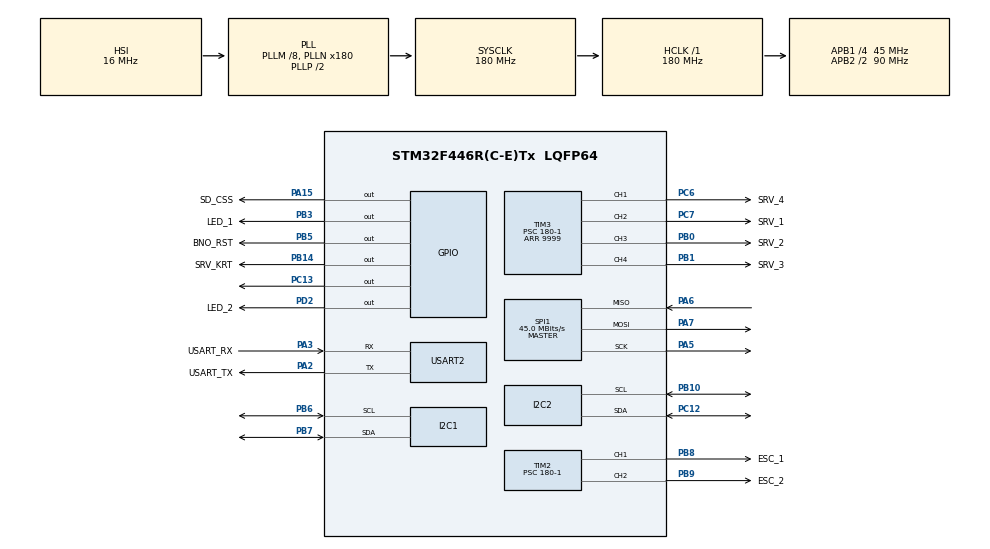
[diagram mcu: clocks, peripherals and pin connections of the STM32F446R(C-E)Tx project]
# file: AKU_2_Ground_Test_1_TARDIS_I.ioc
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FATFS._MAX_SS=4096
FREERTOS.Tasks01=Read_SensorData,3,512,Read_Sensor_Data_Task,Default,NULL,Dynamic,NULL,NULL;Flight_States,2,512,Flight_States_Task,Default,NULL,Dynamic,NULL,NULL;Servo_Control,2,512,Servo_Control_Task,Default,NULL,Dynamic,NULL,NULL;DC_Motor_Contro,2,512,DC_Motor_Control_Task,Default,NULL,Dynamic,NULL,NULL;Uart_to_LTC,0,2048,Uart_to_LTC_Task,Default,NULL,Dynamic,NULL,NULL;Write_to_SD,0,1024,Write_to_SD_Start,Default,NULL,Dynamic,NULL,NULL;System_Check,2,512,System_Check_Start,Default,NULL,Dynamic,NULL,NULL
FREERTOS.configCHECK_FOR_STACK_OVERFLOW=1
FREERTOS.configTOTAL_HEAP_SIZE=45360
FREERTOS.configUSE_NEWLIB_REENTRANT=1
Mcu.Family=STM32F4
Mcu.Name=STM32F446R(C-E)Tx
Mcu.Package=LQFP64
NVIC.PriorityGroup=NVIC_PRIORITYGROUP_4
NVIC.TIM1_UP_TIM10_IRQn=true\:15\:0\:false\:false\:true\:false\:false\:true\:true
NVIC.TimeBase=TIM1_UP_TIM10_IRQn
NVIC.TimeBaseIP=TIM1
NVIC.USART2_IRQn=true\:5\:0\:false\:false\:true\:true\:true\:true\:true
PA13.GPIO_Label=TMS
PA13.Mode=Serial_Wire
PA13.Signal=SYS_JTMS-SWDIO
PA14.GPIO_Label=TCK
PA14.Mode=Serial_Wire
PA14.Signal=SYS_JTCK-SWCLK
PA15.GPIO_Label=SD_CSS
PA15.Signal=GPIO_Output
PA2.GPIO_Label=USART_TX
PA2.Mode=Asynchronous
PA2.Signal=USART2_TX
PA3.GPIO_Label=USART_RX
PA3.Mode=Asynchronous
PA3.Signal=USART2_RX
PA5.Mode=Full_Duplex_Master
PA5.Signal=SPI1_SCK
PA6.Mode=Full_Duplex_Master
PA6.Signal=SPI1_MISO
PA7.Mode=Full_Duplex_Master
PA7.Signal=SPI1_MOSI
PB0.GPIO_Label=SRV_2
PB0.Signal=S_TIM3_CH3
PB1.GPIO_Label=SRV_3
PB1.Signal=S_TIM3_CH4
PB10.Mode=I2C
PB10.Signal=I2C2_SCL
PB14.GPIO_Label=SRV_KRT
PB14.Signal=GPIO_Output
PB3.GPIO_Label=LED_1
PB3.Signal=GPIO_Output
PB5.GPIO_Label=BNO_RST
PB5.Signal=GPIO_Output
PB6.Mode=I2C
PB6.Signal=I2C1_SCL
PB7.Mode=I2C
PB7.Signal=I2C1_SDA
PB8.GPIO_Label=ESC_1
PB8.Signal=S_TIM2_CH1_ETR
PB9.GPIO_Label=ESC_2
PB9.Signal=S_TIM2_CH2
PC12.Mode=I2C
PC12.Signal=I2C2_SDA
PC13.Signal=GPIO_Output
PC14-OSC32_IN.GPIO_Label=LED_3
PC14-OSC32_IN.Mode=LSE-External-Oscillator
PC14-OSC32_IN.Signal=RCC_OSC32_IN
PC15-OSC32_OUT.Mode=LSE-External-Oscillator
PC15-OSC32_OUT.Signal=RCC_OSC32_OUT
PC6.GPIO_Label=SRV_4
PC6.Signal=S_TIM3_CH1
PC7.GPIO_Label=SRV_1
PC7.Signal=S_TIM3_CH2
PD2.GPIO_Label=LED_2
PD2.Signal=GPIO_Output
PH0-OSC_IN.Mode=HSE-External-Oscillator
PH0-OSC_IN.Signal=RCC_OSC_IN
PH1-OSC_OUT.Mode=HSE-External-Oscillator
PH1-OSC_OUT.Signal=RCC_OSC_OUT
ProjectManager.HeapSize=0x200
ProjectManager.StackSize=0x400
ProjectManager.TargetToolchain=STM32CubeIDE
RCC.48MHZClocksFreq_Value=84000000
RCC.AHBFreq_Value=180000000
RCC.APB1CLKDivider=RCC_HCLK_DIV4
RCC.APB1Freq_Value=45000000
RCC.APB1TimFreq_Value=90000000
RCC.APB2CLKDivider=RCC_HCLK_DIV2
RCC.APB2Freq_Value=90000000
RCC.APB2TimFreq_Value=180000000
RCC.CortexFreq_Value=180000000
RCC.FLatency-AdvancedSettings=FLASH_LATENCY_5
RCC.HCLKFreq_Value=180000000
RCC.HSE_VALUE=8000000
RCC.HSI_VALUE=16000000
RCC.PLLM=8
RCC.PLLN=180
RCC.SYSCLKFreq_VALUE=180000000
RCC.SYSCLKSource=RCC_SYSCLKSOURCE_PLLCLK
RCC.USBFreq_Value=180000000
RCC.VCOOutputFreq_Value=360000000
SH.S_TIM2_CH1_ETR.0=TIM2_CH1,PWM Generation1 CH1
SH.S_TIM2_CH2.0=TIM2_CH2,PWM Generation2 CH2
SH.S_TIM3_CH1.0=TIM3_CH1,PWM Generation1 CH1
SH.S_TIM3_CH2.0=TIM3_CH2,PWM Generation2 CH2
SH.S_TIM3_CH3.0=TIM3_CH3,PWM Generation3 CH3
SH.S_TIM3_CH4.0=TIM3_CH4,PWM Generation4 CH4
SPI1.CalculateBaudRate=45.0 MBits/s
SPI1.Direction=SPI_DIRECTION_2LINES
SPI1.Mode=SPI_MODE_MASTER
SPI1.VirtualType=VM_MASTER
TIM2.Channel-PWM\ Generation1\ CH1=TIM_CHANNEL_1
TIM2.Channel-PWM\ Generation2\ CH2=TIM_CHANNEL_2
TIM2.Period=9999
TIM2.Prescaler=180-1
TIM3.Channel-PWM\ Generation1\ CH1=TIM_CHANNEL_1
TIM3.Channel-PWM\ Generation2\ CH2=TIM_CHANNEL_2
TIM3.Channel-PWM\ Generation3\ CH3=TIM_CHANNEL_3
TIM3.Channel-PWM\ Generation4\ CH4=TIM_CHANNEL_4
TIM3.Period=9999
TIM3.Prescaler=180-1
USART2.VirtualMode=VM_ASYNC
VP_FATFS_VS_Generic.Mode=User_defined
VP_FREERTOS_VS_CMSIS_V1.Mode=CMSIS_V1
VP_SYS_VS_tim1.Mode=TIM1
VP_TIM2_VS_ClockSourceINT.Mode=Internal
VP_TIM3_VS_ClockSourceINT.Mode=Internal
board=NUCLEO-F446RE

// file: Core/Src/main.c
/* USER CODE BEGIN Header */
/**
  ******************************************************************************
  * @file           : main.c
  * @brief          : Main program body
  ******************************************************************************
  * @attention
  *
  * Copyright (c) 2024 STMicroelectronics.
  * All rights reserved.
  *
  * This software is licensed under terms that can be found in the LICENSE file
  * in the root directory of this software component.
  * If no LICENSE file comes with this software, it is provided AS-IS.
  *
  ******************************************************************************
  */
/* USER CODE END Header */
#include "main.h"
#include "cmsis_os.h"
#include "fatfs.h"
#include "i2c.h"
#include "spi.h"
#include "tim.h"
#include "usart.h"
#include "gpio.h"

void SystemClock_Config(void);
void MX_FREERTOS_Init(void);

int main(void)
{

  /* MCU Configuration--------------------------------------------------------*/

  /* Reset of all peripherals, Initializes the Flash interface and the Systick. */
  HAL_Init();

  /* Configure the system clock */
  SystemClock_Config();

  /* Initialize all configured peripherals */
  MX_GPIO_Init();
  MX_USART2_UART_Init();
  MX_I2C2_Init();
  MX_TIM2_Init();
  MX_I2C1_Init();
  MX_TIM3_Init();
  MX_SPI1_Init();
  MX_FATFS_Init();

  /* Call init function for freertos objects (in freertos.c) */
  MX_FREERTOS_Init();

  /* Start scheduler */
  osKernelStart();
  /* We should never get here as control is now taken by the scheduler */
  /* Infinite loop */
  while (1)
  {

  }
}

void SystemClock_Config(void)
{
  RCC_OscInitTypeDef RCC_OscInitStruct = {0};
  RCC_ClkInitTypeDef RCC_ClkInitStruct = {0};

  /** Configure the main internal regulator output voltage
  */
  __HAL_RCC_PWR_CLK_ENABLE();
  __HAL_PWR_VOLTAGESCALING_CONFIG(PWR_REGULATOR_VOLTAGE_SCALE1);

  /** Initializes the RCC Oscillators according to the specified parameters
  * in the RCC_OscInitTypeDef structure.
  */
  RCC_OscInitStruct.OscillatorType = RCC_OSCILLATORTYPE_HSI;
  RCC_OscInitStruct.HSIState = RCC_HSI_ON;
  RCC_OscInitStruct.HSICalibrationValue = RCC_HSICALIBRATION_DEFAULT;
  RCC_OscInitStruct.PLL.PLLState = RCC_PLL_ON;
  RCC_OscInitStruct.PLL.PLLSource = RCC_PLLSOURCE_HSI;
  RCC_OscInitStruct.PLL.PLLM = 8;
  RCC_OscInitStruct.PLL.PLLN = 180;
  RCC_OscInitStruct.PLL.PLLP = RCC_PLLP_DIV2;
  RCC_OscInitStruct.PLL.PLLQ = 2;
  RCC_OscInitStruct.PLL.PLLR = 2;
  if (HAL_RCC_OscConfig(&RCC_OscInitStruct) != HAL_OK)
  {
    Error_Handler();
  }

  /** Activate the Over-Drive mode
  */
  if (HAL_PWREx_EnableOverDrive() != HAL_OK)
  {
    Error_Handler();
  }

  /** Initializes the CPU, AHB and APB buses clocks
  */
  RCC_ClkInitStruct.ClockType = RCC_CLOCKTYPE_HCLK|RCC_CLOCKTYPE_SYSCLK
                              |RCC_CLOCKTYPE_PCLK1|RCC_CLOCKTYPE_PCLK2;
  RCC_ClkInitStruct.SYSCLKSource = RCC_SYSCLKSOURCE_PLLCLK;
  RCC_ClkInitStruct.AHBCLKDivider = RCC_SYSCLK_DIV1;
  RCC_ClkInitStruct.APB1CLKDivider = RCC_HCLK_DIV4;
  RCC_ClkInitStruct.APB2CLKDivider = RCC_HCLK_DIV2;

  if (HAL_RCC_ClockConfig(&RCC_ClkInitStruct, FLASH_LATENCY_5) != HAL_OK)
  {
    Error_Handler();
  }
}

void HAL_TIM_PeriodElapsedCallback(TIM_HandleTypeDef *htim)
{
  if (htim->Instance == TIM1) {
    HAL_IncTick();
  }
}

void Error_Handler(void)
{
  __disable_irq();
  while (1)
  {
  }
}

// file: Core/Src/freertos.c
/* USER CODE BEGIN Header */
/**
  ******************************************************************************
  * File Name          : freertos.c
  * Description        : Code for freertos applications
  ******************************************************************************
  * @attention
  *
  * Copyright (c) 2024 STMicroelectronics.
  * All rights reserved.
  *
  * This software is licensed under terms that can be found in the LICENSE file
  * in the root directory of this software component.
  * If no LICENSE file comes with this software, it is provided AS-IS.
  *
  ******************************************************************************
  */
/* USER CODE END Header */

#include "FreeRTOS.h"
#include "task.h"
#include "main.h"
#include "cmsis_os.h"

/* USER CODE BEGIN Includes */
#include "DCC_Functions.h"
#include "DCC_Variables.h"
#include "DCC_Motor_Control.h"
/* USER CODE END Includes */

osThreadId Read_SensorDataHandle;
osThreadId Flight_StatesHandle;
osThreadId Servo_ControlHandle;
osThreadId DC_Motor_ControHandle;
osThreadId Uart_to_LTCHandle;
osThreadId Write_to_SDHandle;
osThreadId System_CheckHandle;

void Read_Sensor_Data_Task(void const * argument);
void Flight_States_Task(void const * argument);
void Servo_Control_Task(void const * argument);
void DC_Motor_Control_Task(void const * argument);
void Uart_to_LTC_Task(void const * argument);
void Write_to_SD_Start(void const * argument);
void System_Check_Start(void const * argument);

void MX_FREERTOS_Init(void); /* (MISRA C 2004 rule 8.1) */

/* GetIdleTaskMemory prototype (linked to static allocation support) */
void vApplicationGetIdleTaskMemory( StaticTask_t **ppxIdleTaskTCBBuffer, StackType_t **ppxIdleTaskStackBuffer, uint32_t *pulIdleTaskStackSize );

/* Hook prototypes */
void vApplicationStackOverflowHook(xTaskHandle xTask, signed char *pcTaskName);

/* USER CODE BEGIN 4 */
__weak void vApplicationStackOverflowHook(xTaskHandle xTask, signed char *pcTaskName)
{
   /* Run time stack overflow checking is performed if
   configCHECK_FOR_STACK_OVERFLOW is defined to 1 or 2. This hook function is
   called if a stack overflow is detected. */
}
/* USER CODE END 4 */

/* USER CODE BEGIN GET_IDLE_TASK_MEMORY */
static StaticTask_t xIdleTaskTCBBuffer;
static StackType_t xIdleStack[configMINIMAL_STACK_SIZE];

void vApplicationGetIdleTaskMemory( StaticTask_t **ppxIdleTaskTCBBuffer, StackType_t **ppxIdleTaskStackBuffer, uint32_t *pulIdleTaskStackSize )
{
  *ppxIdleTaskTCBBuffer = &xIdleTaskTCBBuffer;
  *ppxIdleTaskStackBuffer = &xIdleStack[0];
  *pulIdleTaskStackSize = configMINIMAL_STACK_SIZE;
  /* place for user code */
}
/* USER CODE END GET_IDLE_TASK_MEMORY */

void MX_FREERTOS_Init(void) {

  /* Create the thread(s) */
  /* definition and creation of Read_SensorData */
  osThreadDef(Read_SensorData, Read_Sensor_Data_Task, osPriorityRealtime, 0, 512);
  Read_SensorDataHandle = osThreadCreate(osThread(Read_SensorData), NULL);

  /* definition and creation of Flight_States */
  osThreadDef(Flight_States, Flight_States_Task, osPriorityHigh, 0, 512);
  Flight_StatesHandle = osThreadCreate(osThread(Flight_States), NULL);

  /* definition and creation of Servo_Control */
  osThreadDef(Servo_Control, Servo_Control_Task, osPriorityHigh, 0, 512);
  Servo_ControlHandle = osThreadCreate(osThread(Servo_Control), NULL);

  /* definition and creation of DC_Motor_Contro */
  osThreadDef(DC_Motor_Contro, DC_Motor_Control_Task, osPriorityHigh, 0, 512);
  DC_Motor_ControHandle = osThreadCreate(osThread(DC_Motor_Contro), NULL);

  /* definition and creation of Uart_to_LTC */
  osThreadDef(Uart_to_LTC, Uart_to_LTC_Task, osPriorityNormal, 0, 2048);
  Uart_to_LTCHandle = osThreadCreate(osThread(Uart_to_LTC), NULL);

  /* definition and creation of Write_to_SD */
  osThreadDef(Write_to_SD, Write_to_SD_Start, osPriorityNormal, 0, 1024);
  Write_to_SDHandle = osThreadCreate(osThread(Write_to_SD), NULL);

  /* definition and creation of System_Check */
  osThreadDef(System_Check, System_Check_Start, osPriorityHigh, 0, 512);
  System_CheckHandle = osThreadCreate(osThread(System_Check), NULL);

}

void Read_Sensor_Data_Task(void const * argument)
{
  /* USER CODE BEGIN Read_Sensor_Data_Task */
	init_IMU();
	initBarometer();
  /* Infinite loop */
  for(;;)
  {
	read_IMU();
	readAltitude();
    osDelay(1);
  }
  /* USER CODE END Read_Sensor_Data_Task */
}

void Flight_States_Task(void const * argument)
{
  for(;;)
  {
    osDelay(1);
  }
}

void Servo_Control_Task(void const * argument)
{
  for(;;)
  {
    osDelay(1);
  }
}

void DC_Motor_Control_Task(void const * argument)
{
  /* USER CODE BEGIN DC_Motor_Control_Task */
	init_DC_Motor();
	configurate_ESC();
  /* Infinite loop */
  for(;;)
  {
    osDelay(1);
  }
  /* USER CODE END DC_Motor_Control_Task */
}

void Uart_to_LTC_Task(void const * argument)
{
  for(;;)
  {
    osDelay(1);
  }
}

void Write_to_SD_Start(void const * argument)
{
  /* USER CODE BEGIN Write_to_SD_Start */
	SD_init();
  /* Infinite loop */
  for(;;)
  {
	SD_write();
    osDelay(1);
  }
  /* USER CODE END Write_to_SD_Start */
}

void System_Check_Start(void const * argument)
{
  for(;;)
  {
    osDelay(1);
  }
}
